# N575F145_v1 register map
File version: 1.0
Registers are 32-bit, read-write, reset 0x0 unless marked. A register's access mark holds for its fields unless they carry their own. Offsets are from the block's base; [hi:lo] are bit positions.

## ACMP — ACMP Register Map
Base 0x400D0000
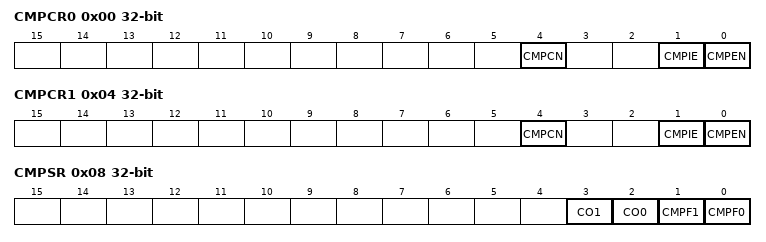
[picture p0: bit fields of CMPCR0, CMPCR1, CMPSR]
0x00 CMPCR0 — Analog Comparator 0 Control Register
  [4] CMPCN — Comparator0 Negative Input Select
    0=VBG, Bandgap reference voltage = 1.2V; 1=VMID reference voltage = VCCA/2
  [1] CMPIE — CMP0 Interrupt Enable
    0=Disable CMP0 interrupt function; 1=Enable CMP0 interrupt function
  [0] CMPEN — Comparator Enable
    0=Disable; 1=Enable
0x04 CMPCR1 — Analog Comparator 1 Control Register
  [4] CMPCN — Comparator1 Negative Input Select
    0=GPIOB[7]; 1=VBG, Bandgap reference voltage = 1.2V
  [1] CMPIE — CMP1 Interrupt Enable
    0=Disable CMP1interrupt function; 1=Enable CMP1 interrupt function
  [0] CMPEN — Comparator Enable
    0=Disable; 1=Enable
0x08 CMPSR (reset mask 0xFFFFFF00) — Comparator Status Register
  [3] CO1 — Comparator1 Output. Synchronized to the APB clock to allow reading by software. Cleared when the comparator is disabled (CMP1EN = 0).
  [2] CO0 — Comparator0 Output. Synchronized to the APB clock to allow reading by software. Cleared when the comparator is disabled (CMP0EN = 0).
  [1] CMPF1 — Compare 1 Flag. This bit is set by hardware whenever the comparator output changes state. This bit will cause a hardware interrupt if enabled. This bit is cleared by writing 1 to itself.
  [0] CMPF0 — Compare 0 Flag. This bit is set by hardware whenever the comparator output changes state. This bit will cause a hardware interrupt if enabled. This bit is cleared by writing 1 to itself.
0x0C CMPSEL — Comparator Select Register
  [2:0] CMPSEL — Comparator0 GPIO Selection. GPIOB[CMPSEL] is the active analog GPIO input selected to Comparator 0 positive input.

## ALC — ALC Register Map
Base 0x400B0048
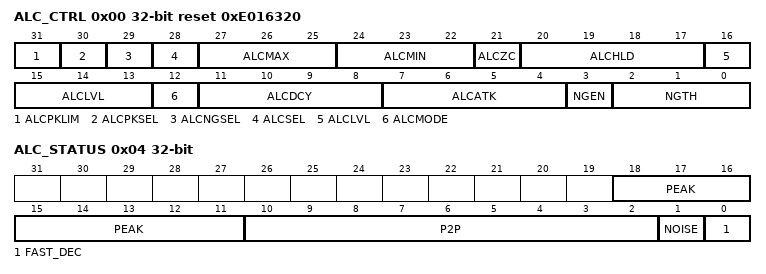
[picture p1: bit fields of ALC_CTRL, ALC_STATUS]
0x00 ALC_CTRL reset 0xE016320 — ALC Control Register
  [31] ALCPKLIM — ALC peak limiter enable
    0=enable fast decrement when signal exceeds 87.5% of full scale (default); 1=disable fast decrement when signal exceeds 87.5% of full scale
  [30] ALCPKSEL — ALC gain peak detector select
    0=use absolute peak value for ALC training (default); 1=use peak-to-peak value for ALC training
  [29] ALCNGSEL — ALC noise gate peak detector select
    0=use peak-to-peak value for noise gate threshold determination (default); 1=use absolute peak value for noise gate threshold determination
  [28] ALCSEL — ALC select
    0=ALC disabled (default); 1=ALC enabled
  [27:25] ALCMAX — ALC Maximum Gain
    0=-6.75 dB; 1=-0.75 dB; 2=+5.25 dB; 3=+11.25 dB; 4=+17.25 dB; 5=+23.25 dB; 6=+29.25 dB; 7=+35.25 dB
  [24:22] ALCMIN — ALC Minimum Gain
    0=-12 dB; 1=-6 dB; 2=0 dB; 3=6 dB; 4=12 dB; 5=18 dB; 6=24 dB; 7=30 dB
  [21] ALCZC — ALC Zero Crossing
    0=zero crossing disabled; 1=zero crossing enabled
  [20:17] ALCHLD — ALC Hold Time (Value: 0~10). Hold Time = (2^ALCHLD) ms
  [16:13] ALCLVL — ALC Target Level
    0=-28.5 dB; 1=-27 dB; 2=-25.5 dB; 3=-24 dB; 4=-22.5 dB; 5=-21 dB; 6=-19.5 dB; 7=-18 dB; 8=-16.5 dB; 9=-15 dB; 10=-13.5 dB; 11=-12 dB; 12=-10.5 dB; 13=-9 dB; 14=-7.5 dB; 15=-6 dB
  [12] ALCMODE
    0=ALC normal operation mode; 1=ALC limiter mode
  [11:8] ALCDCY — ALC Decay Time (Value: 0~10). When ALCMODE = 0, Range: 125us to 128ms. When ALCMODE = 1, Range: 31us to 32ms (time doubles with every step)
  [7:4] ALCATK — ALC Attack Time (Value: 0~10). When ALCMODE = 0, Range: 500us to 512ms. When ALCMODE = 1,Range: 125us to 128ms (Both ALC time doubles with every step)
  [3] NGEN — Noise Gate Enable
    0=Noise gate disabled; 1=Noise gate enabled
  [2:0] NGTH — Noise Gate Threshold. Boost disabled: Threshold = (-81+6xNGTH) dB. Boost enabled: Threshold = (-87+6xNGTH) dB
0x04 ALC_STATUS ro
  [18:11] PEAK — Peak Value. 9 MSBs of measured absolute peak value
  [10:2] P2P — Peak-To-Peak Value. 9 MSBs of measured peak-to-peak value
  [1] NOISE — Noise Flag. Asserted when signal level is detected to be below NGTH
  [0] FAST_DEC — Clipping Flag. Asserted when signal level is detected to be above 87.5% of full scale
0x08 ALC_INT — ALC interrupt register
  [0] ALC_INT — ALC interrupt. This interrupt flag asserts whenever the interrupt is enabled and the PGA gain is updated, either through an ALC change with the ALC enabled or through a PGA gain write with the ALC disabled. Write a 1 to this register to clear.
0x0C ALC_INTEN — ALC interrupt enable register
  [0] ALC_INTEN — ALC Interrupt Enable
    0=ALC_INT disabled; 1=ALC_INT enabled

## BIQ — BIQ Register Map
Base 0x400B0000
0x00 BIQ_COEFF0 reset 0xD010 — Coefficient b0 In H(z) Transfer Function (3.16 format) - 1st stage BIQ Coefficients
0x04 BIQ_COEFF1 reset 0x1C020 — Coefficient b1 In H(z) Transfer Function (3.16 format) - 1st stage BIQ Coefficients
0x08 BIQ_COEFF2 reset 0x1C020 — Coefficient b2 In H(z) Transfer Function (3.16 format) - 1st stage BIQ Coefficients
0x0C BIQ_COEFF3 reset 0x1AD66 — Coefficient a1 In H(z) Transfer Function (3.16 format) - 1st stage BIQ Coefficients
0x10 BIQ_COEFF4 reset 0xD1DC — Coefficient a2 In H(z) Transfer Function (3.16 format) - 1st stage BIQ Coefficients
0x14 BIQ_COEFF5 reset 0xC1D0 — Coefficient b0 In H(z) Transfer Function (3.16 format) - 2nd stage BIQ Coefficients
0x18 BIQ_COEFF6 reset 0x183A0 — Coefficient b1 In H(z) Transfer Function (3.16 format) - 2nd stage BIQ Coefficients
0x1C BIQ_COEFF7 reset 0xC1D0 — Coefficient b2 In H(z) Transfer Function (3.16 format) - 2nd stage BIQ Coefficients
0x20 BIQ_COEFF8 reset 0x17445 — Coefficient a1 In H(z) Transfer Function (3.16 format) - 2nd stage BIQ Coefficients
0x24 BIQ_COEFF9 reset 0x92F6 — Coefficient a2 In H(z) Transfer Function (3.16 format) - 2nd stage BIQ Coefficients
0x28 BIQ_COEFF10 reset 0xB3CC — Coefficient b0 In H(z) Transfer Function (3.16 format) - 3rd stage BIQ Coefficients
0x2C BIQ_COEFF11 reset 0x16798 — Coefficient b1 In H(z) Transfer Function (3.16 format) - 3rd stage BIQ Coefficients
0x30 BIQ_COEFF12 reset 0xB3CC — Coefficient b2 In H(z) Transfer Function (3.16 format) - 3rd stage BIQ Coefficients
0x34 BIQ_COEFF13 reset 0x1595D — Coefficient a1 In H(z) Transfer Function (3.16 format) - 3rd stage BIQ Coefficients
0x38 BIQ_COEFF14 reset 0x75D2 — Coefficient a2 In H(z) Transfer Function (3.16 format) - 3rd stage BIQ Coefficients
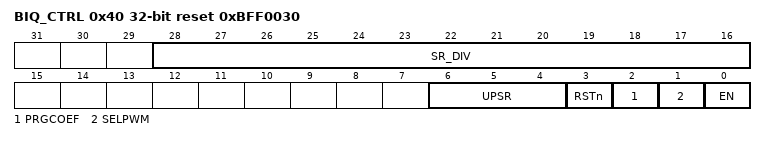
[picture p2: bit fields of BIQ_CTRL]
0x40 BIQ_CTRL reset 0xBFF0030 — BIQ Control Register
  [28:16] SR_DIV — Sample Rate Divider. This register is used to program the operating sampling rate of the biquad filter. The sample rate is defined as. HCLK/(SR_DIV+1). Default to 3071 so the sampling rate is 16K when HCLK is 49.152MHz.
  [6:4] UPSR — DPWM Path Up Sample Rate (From SR_DIV Result). This register is only used when SELPWM is set to 1. The operating sample rate for the biquad filter will be (UPSR+1)*HCLK/(SR_DIV+1). Default value for this register is 3.
  [3] RSTn — Move BIQ Out Of Reset State
    0=BIQ filter is in reset state; 1=When this bit is on, the default coefficients will be downloaded to the coefficient ram automatically in 32 internal system clocks. Processor must delay enough time before changing the coefficients or turn the BIQ on
  [2] PRGCOEF — Programming Mode Coefficient Control Bit. This bit must be turned off when BIQEN in on.
    0=Coefficient RAM is in normal mode; 1=coefficient RAM is under programming mode
  [1] SELPWM — AC Path Selection For BIQ
    0=used in ADC path; 1=used in DPWM path
  [0] EN — BIQ Filter Start To Run
    0=BIQ filter is not processing; 1=BIQ filter is on
